# comp register map
Vendor: Texas Instruments
Peripheral module from a debugger description file (folder sc4ce290ncpz).
Registers are 32-bit, read-write, no defined reset value unless marked. A register's access mark holds for its fields unless they carry their own. Offsets are as the file gives them; lines under a group give offsets from that group; [hi:lo] are bit positions; {n}, {i} and the like mark numbered series; 'fields as' and 'values as' point back to an identical list; <NAME> marks a mode.

## COMP — Comparator register offsets
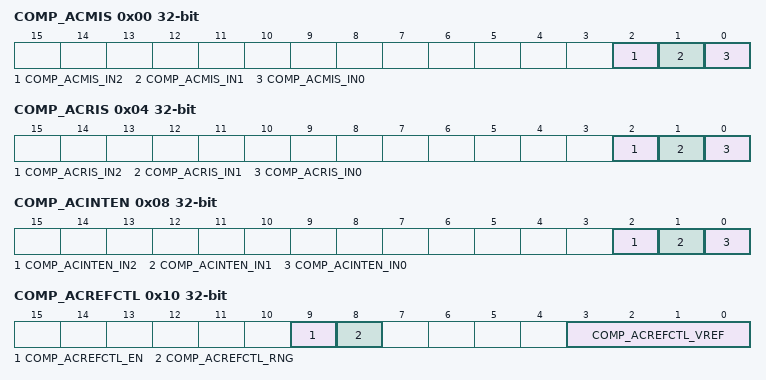
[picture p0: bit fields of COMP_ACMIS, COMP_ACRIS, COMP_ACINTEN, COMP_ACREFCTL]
0x00 COMP_ACMIS — Analog Comparator Masked Interrupt Status
  [2] COMP_ACMIS_IN2 — Comparator 2 Masked Interrupt Status
  [1] COMP_ACMIS_IN1 — Comparator 1 Masked Interrupt Status
  [0] COMP_ACMIS_IN0 — Comparator 0 Masked Interrupt Status
0x04 COMP_ACRIS ro — Analog Comparator Raw Interrupt Status
  [2] COMP_ACRIS_IN2 — Comparator 2 Interrupt Status
  [1] COMP_ACRIS_IN1 — Comparator 1 Interrupt Status
  [0] COMP_ACRIS_IN0 — Comparator 0 Interrupt Status
0x08 COMP_ACINTEN — Analog Comparator Interrupt Enable
  [2] COMP_ACINTEN_IN2 — Comparator 2 Interrupt Enable
  [1] COMP_ACINTEN_IN1 — Comparator 1 Interrupt Enable
  [0] COMP_ACINTEN_IN0 — Comparator 0 Interrupt Enable
0x10 COMP_ACREFCTL — Analog Comparator Reference Voltage Control
  [9] COMP_ACREFCTL_EN — Resistor Ladder Enable
  [8] COMP_ACREFCTL_RNG — Resistor Ladder Range
  [3:0] COMP_ACREFCTL_VREF — Resistor Ladder Voltage Ref
{0x20+0x20*i} COMP_ACSTAT{i} ro (i=0..2) — Analog Comparator Status {i}
  [1] COMP_ACSTAT{i}_OVAL — Comparator Output Value
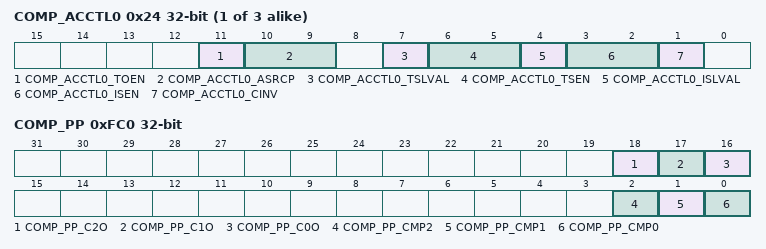
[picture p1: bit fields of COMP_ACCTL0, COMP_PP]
{0x24+0x20*i} COMP_ACCTL{i} (i=0..2) — Analog Comparator Control {i}
  [11] COMP_ACCTL{i}_TOEN — Trigger Output Enable
  [10:9] COMP_ACCTL{i}_ASRCP — Analog Source Positive
    0=COMP_ACCTL{i}_ASRCP_PIN (Pin value of Cn+); 1=COMP_ACCTL{i}_ASRCP_PIN0 (Pin value of C0+); 2=COMP_ACCTL{i}_ASRCP_REF (Internal voltage reference)
  [7] COMP_ACCTL{i}_TSLVAL — Trigger Sense Level Value
  [6:5] COMP_ACCTL{i}_TSEN — Trigger Sense
    0=COMP_ACCTL{i}_TSEN_LEVEL (Level sense, see TSLVAL); 1=COMP_ACCTL{i}_TSEN_FALL (Falling edge); 2=COMP_ACCTL{i}_TSEN_RISE (Rising edge); 3=COMP_ACCTL{i}_TSEN_BOTH (Either edge)
  [4] COMP_ACCTL{i}_ISLVAL — Interrupt Sense Level Value
  [3:2] COMP_ACCTL{i}_ISEN — Interrupt Sense
    0=COMP_ACCTL{i}_ISEN_LEVEL (Level sense, see ISLVAL); 1=COMP_ACCTL{i}_ISEN_FALL (Falling edge); 2=COMP_ACCTL{i}_ISEN_RISE (Rising edge); 3=COMP_ACCTL{i}_ISEN_BOTH (Either edge)
  [1] COMP_ACCTL{i}_CINV — Comparator Output Invert
0xFC0 COMP_PP ro — Analog Comparator Peripheral Properties
  [18] COMP_PP_C2O — Comparator Output 2 Present
  [17] COMP_PP_C1O — Comparator Output 1 Present
  [16] COMP_PP_C0O — Comparator Output 0 Present
  [2] COMP_PP_CMP2 — Comparator 2 Present
  [1] COMP_PP_CMP1 — Comparator 1 Present
  [0] COMP_PP_CMP0 — Comparator 0 Present
